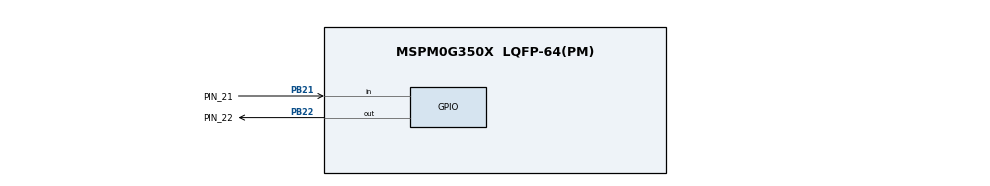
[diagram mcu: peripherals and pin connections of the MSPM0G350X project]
/**
 * @cliArgs --device "MSPM0G350X" --part "Default" --package "LQFP-64(PM)" --product "mspm0_sdk@2.10.00.04"
 * @versions {"tool":"1.26.2+4477"}
 */
const GPIO   = scripting.addModule("/ti/driverlib/GPIO", {}, false);
const LED    = GPIO.addInstance();
const KEYIN  = GPIO.addInstance();
const SYSCTL = scripting.addModule("/ti/driverlib/SYSCTL");

LED.$name                         = "LED1";
LED.associatedPins[0].$name       = "PIN_22";
LED.associatedPins[0].pin.$assign = "PB22";

KEYIN.$name                              = "KEY";
KEYIN.associatedPins[0].$name            = "PIN_21";
KEYIN.associatedPins[0].direction        = "INPUT";
KEYIN.associatedPins[0].internalResistor = "PULL_UP";
KEYIN.associatedPins[0].interruptEn      = true;
KEYIN.associatedPins[0].polarity         = "FALL";
KEYIN.associatedPins[0].pin.$assign      = "PB21";
const Board = scripting.addModule("/ti/driverlib/Board", {}, false);

SYSCTL.forceDefaultClkConfig = true;
Board.peripheral.$suggestSolution          = "DEBUGSS";
Board.peripheral.swclkPin.$suggestSolution = "PA20";
Board.peripheral.swdioPin.$suggestSolution = "PA19";
SYSCTL.peripheral.$suggestSolution         = "SYSCTL";
